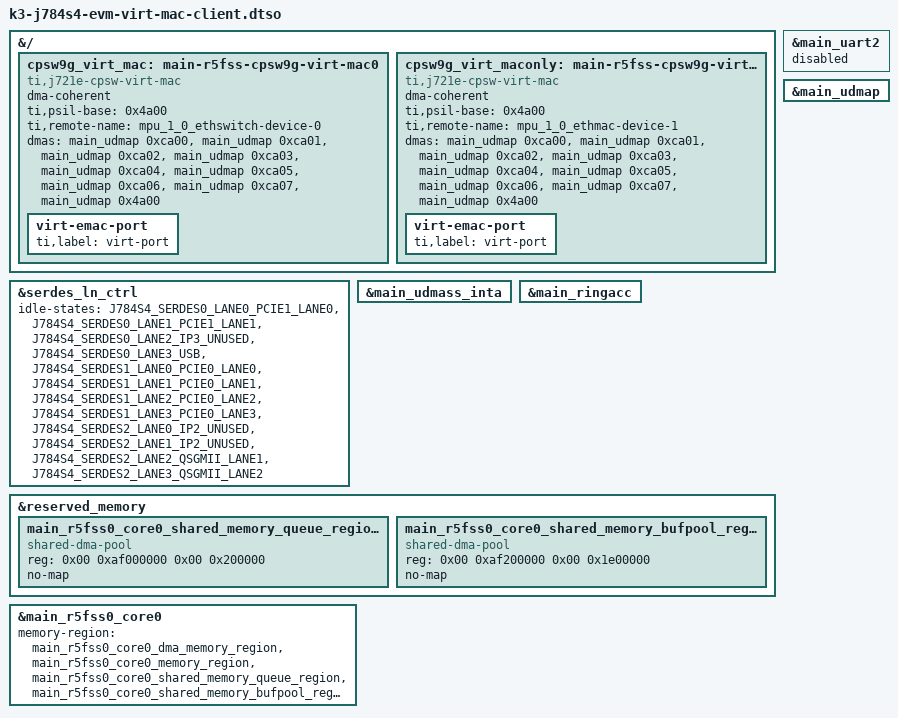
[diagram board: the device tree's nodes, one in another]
// SPDX-License-Identifier: GPL-2.0
/**
 * DT Overlay for enabling CPSW Virt MAC Client driver in Linux to interface with EthFw via the
 * Linux MAC Only port as well as the Switch Ports of the CPSW9G CPSW instance.
 *
 * Copyright (C) 2023 Texas Instruments Incorporated - https://www.ti.com/
 */

/dts-v1/;
/plugin/;

#include <dt-bindings/mux/ti-serdes.h>
#include <dt-bindings/phy/phy-cadence.h>

&{/} {
	cpsw9g_virt_mac: main-r5fss-cpsw9g-virt-mac0 {
		compatible = "ti,j721e-cpsw-virt-mac";
		dma-coherent;
		ti,psil-base = <0x4a00>;
		ti,remote-name = "mpu_1_0_ethswitch-device-0";

		dmas = <&main_udmap 0xca00>,
		       <&main_udmap 0xca01>,
		       <&main_udmap 0xca02>,
		       <&main_udmap 0xca03>,
		       <&main_udmap 0xca04>,
		       <&main_udmap 0xca05>,
		       <&main_udmap 0xca06>,
		       <&main_udmap 0xca07>,
		       <&main_udmap 0x4a00>;
		dma-names = "tx0", "tx1", "tx2", "tx3",
			    "tx4", "tx5", "tx6", "tx7",
			    "rx";

		virt-emac-port {
			ti,label = "virt-port";
			/* local-mac-address = [0 0 0 0 0 0]; */
		};
	};

	cpsw9g_virt_maconly: main-r5fss-cpsw9g-virt-mac1 {
		compatible = "ti,j721e-cpsw-virt-mac";
		dma-coherent;
		ti,psil-base = <0x4a00>;
		ti,remote-name = "mpu_1_0_ethmac-device-1";

		dmas = <&main_udmap 0xca00>,
		       <&main_udmap 0xca01>,
		       <&main_udmap 0xca02>,
		       <&main_udmap 0xca03>,
		       <&main_udmap 0xca04>,
		       <&main_udmap 0xca05>,
		       <&main_udmap 0xca06>,
		       <&main_udmap 0xca07>,
		       <&main_udmap 0x4a00>;
		dma-names = "tx0", "tx1", "tx2", "tx3",
			    "tx4", "tx5", "tx6", "tx7",
			    "rx";

		virt-emac-port {
			ti,label = "virt-port";
			/* local-mac-address = [0 0 0 0 0 0]; */
		};
	};
};

/* uart2 is assigned to cpsw9g eth-switch fw running on remote CPU core */
&main_uart2 {
	status = "reserved";
};

&serdes_ln_ctrl {
	idle-states = <J784S4_SERDES0_LANE0_PCIE1_LANE0>, <J784S4_SERDES0_LANE1_PCIE1_LANE1>,
		      <J784S4_SERDES0_LANE2_IP3_UNUSED>, <J784S4_SERDES0_LANE3_USB>,
		      <J784S4_SERDES1_LANE0_PCIE0_LANE0>, <J784S4_SERDES1_LANE1_PCIE0_LANE1>,
		      <J784S4_SERDES1_LANE2_PCIE0_LANE2>, <J784S4_SERDES1_LANE3_PCIE0_LANE3>,
		      <J784S4_SERDES2_LANE0_IP2_UNUSED>, <J784S4_SERDES2_LANE1_IP2_UNUSED>,
		      <J784S4_SERDES2_LANE2_QSGMII_LANE1>, <J784S4_SERDES2_LANE3_QSGMII_LANE2>;
};

&main_udmass_inta {
	status = "okay";
};

&main_ringacc {
	status = "okay";
};

&main_udmap {
	status = "okay";
};

/* Reserve shared memory for inter-core network communication */
&reserved_memory {
	#address-cells = <2>;
	#size-cells = <2>;

	main_r5fss0_core0_shared_memory_queue_region:r5f-virtual-eth-queues@af000000 {
		compatible = "shared-dma-pool";
		reg = <0x00 0xaf000000 0x00 0x200000>;
		no-map;
	};

	main_r5fss0_core0_shared_memory_bufpool_region:r5f-virtual-eth-buffers@af200000 {
		compatible = "shared-dma-pool";
		reg = <0x00 0xaf200000 0x00 0x1e00000>;
		no-map;
	};
};

&main_r5fss0_core0 {
	memory-region = <&main_r5fss0_core0_dma_memory_region>,
			<&main_r5fss0_core0_memory_region>,
			<&main_r5fss0_core0_shared_memory_queue_region>,
			<&main_r5fss0_core0_shared_memory_bufpool_region>;
};
